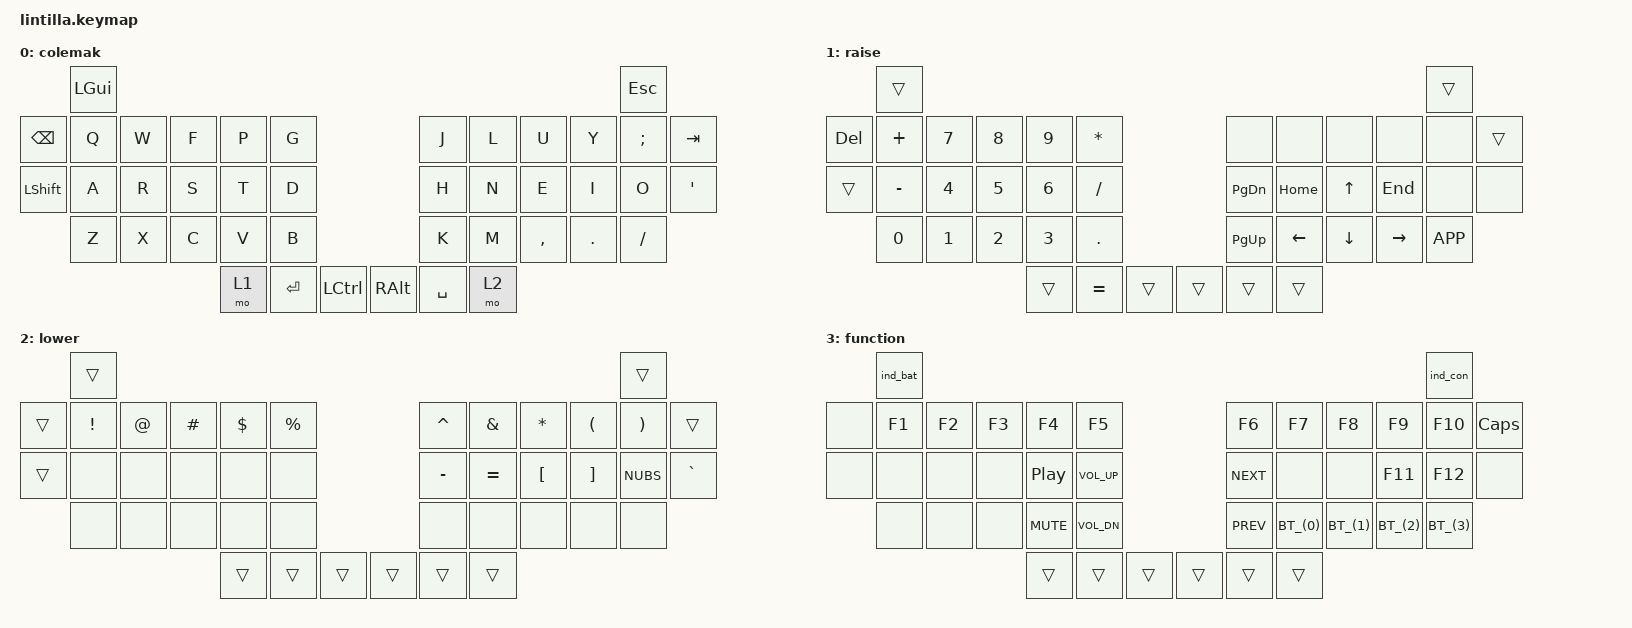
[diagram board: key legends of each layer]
#include <behaviors.dtsi>
#include <dt-bindings/zmk/bt.h>
#include <dt-bindings/zmk/keys.h>
#include <dt-bindings/zmk/outputs.h>
#include <behaviors/rgbled_widget.dtsi>

// Multiple mods
#define GS(key) &kp LG(LS(key))
#define GCS(key) &kp LG(LC(LS(key)))
#define HYPR(key) &kp LG(LA(LC(LS(key))))

// Shortcuts for home row mods
#define Glb &hm GLOBE
#define Sft &hm LSHFT
#define Ctl &hm LCTRL
#define Opt &hm LALT
#define Cmd &hm LGUI
#define Alt &hm RALT
 
// Magic bluetooth button
#define BT_(btnum) &bt_key btnum btnum

/ {
    behaviors {
        bt_key: magic_bluetooth_key {
            compatible = "zmk,behavior-hold-tap";
            #binding-cells = <2>;
            flavor = "tap-preferred";
            tapping-term-ms = <500>;
            bindings = <&bt_clr>, <&bt_sel>;
        };

        hm: homerow_mod {
            compatible = "zmk,behavior-hold-tap";
            #binding-cells = <2>;
            tapping-term-ms = <300>;
            require-prior-idle-ms = <150>;
            quick-tap-ms = <0>;
            flavor = "tap-preferred";
            bindings = <&kp>, <&kp>;
        };

        lsscw: layer_sticky_shift_caps_word {
            compatible = "zmk,behavior-hold-tap";
            #binding-cells = <2>;
            flavor = "balanced";
            tapping-term-ms = <200>;
            bindings = <&mo>, <&sscw>;
        };

        mcs: mod_comma_semi {
            compatible = "zmk,behavior-mod-morph";
            #binding-cells = <0>;
            bindings = <&kp COMMA>, <&kp SEMI>;
            mods = <(MOD_LSFT|MOD_RSFT)>;
        };

        mdc: mod_dot_colon {
            compatible = "zmk,behavior-mod-morph";
            #binding-cells = <0>;
            bindings = <&kp DOT>, <&kp COLON>;
            mods = <(MOD_LSFT|MOD_RSFT)>;
        };

        msb: mod_slash_back {
            compatible = "zmk,behavior-mod-morph";
            #binding-cells = <0>;
            bindings = <&kp SLASH>, <&kp BACKSLASH>;
            mods = <(MOD_LSFT|MOD_RSFT)>;
        };

        sscw: sticky_shift_caps_word {
            compatible = "zmk,behavior-mod-morph";
            #binding-cells = <0>;
            bindings = <&sk LSHIFT>, <&caps_word>;
            mods = <(MOD_LSFT|MOD_RSFT)>;
        };
    };

    conditional_layers {
        compatible = "zmk,conditional-layers";
        function_layer {
            if-layers = <1 2>;
            then-layer = <3>;
        };
    };

    macros {
        bt_clr: bluetooth_clear {
            compatible = "zmk,behavior-macro-one-param";
            #binding-cells = <1>;
            bindings = <&macro_param_1to1 &bt_sel MACRO_PLACEHOLDER>, <&bt BT_CLR>;
        };

        bt_sel: bluetooth_select {
            compatible = "zmk,behavior-macro-one-param";
            #binding-cells = <1>;
            bindings = <&out OUT_BLE>, <&macro_param_1to2 &bt BT_SEL MACRO_PLACEHOLDER>;
        };

        flash: dongle_bootloader {
            compatible = "zmk,behavior-macro-one-param";
            #binding-cells = <1>;
            bindings = <&macro_param_1to1 &to MACRO_PLACEHOLDER>, <&bootloader>;
        };
    };

    keymap {
        compatible = "zmk,keymap";

        qwerty {
//                       ┏━━━━━━━━━━━━━━━━━━━━━━━━━┓
            display-name = "colemak"                ;
//                       ┗━━━━━━━━━━━━━━━━━━━━━━━━━┛
            bindings = <
//         ┏━━━━━━━┓                                                                                          ┏━━━━━━━┓
//         ┃  WIN  ┃                                                                                          ┃  ESC  ┃
            &kp LGUI                                                                                           &kp ESC
//         ┃       ┃                                                                                          ┃       ┃
// ┏━━━━━━━╋━━━━━━━╋━━━━━━━┳━━━━━━━┳━━━━━━━┳━━━━━━━┓                          ┏━━━━━━━┳━━━━━━━┳━━━━━━━┳━━━━━━━╋━━━━━━━╋━━━━━━━┓
// ┃  BSPC ┃   Q   ┃   W   ┃   F   ┃   P   ┃   G   ┃                          ┃   J   ┃   L   ┃   U   ┃   Y   ┃   :   ┃  TAB  ┃
   &kp BSPC  &kp Q   &kp W   &kp F   &kp P   &kp G                              &kp J   &kp L   &kp U   &kp Y  &kp SEMI &kp TAB
// ┣━━━━━━━╋━━━━━━━╋━━━━━━━╋━━━━━━━╋━━━━━━━╋━━━━━━━┫                          ┣━━━━━━━╋━━━━━━━╋━━━━━━━╋━━━━━━━╋━━━━━━━╋━━━━━━━┫
// ┃ SHIFT ┃   A   ┃   R   ┃   S   ┃   T   ┃   D   ┃                          ┃   H   ┃   N   ┃   E   ┃   I   ┃   O   ┃   '   ┃
  &kp LSHFT  &kp A   &kp R   &kp S   &kp T   &kp D                              &kp H   &kp N   &kp E   &kp I  &kp O   &kp SQT
// ┃       ┃       ┃       ┃       ┃       ┃       ┃                          ┃       ┃       ┃       ┃       ┃       ┃       ┃
// ┗━━━━━━━╋━━━━━━━╋━━━━━━━╋━━━━━━━╋━━━━━━━╋━━━━━━━┫                          ┣━━━━━━━╋━━━━━━━╋━━━━━━━╋━━━━━━━╋━━━━━━━╋━━━━━━━┛
//         ┃   Z   ┃   X   ┃   C   ┃   V   ┃   B   ┃                          ┃   K   ┃   M   ┃   ,   ┃   .   ┃  / \  ┃
             &kp Z   &kp X   &kp C   &kp V   &kp B                              &kp K   &kp M &kp COMMA &kp DOT &kp FSLH
//         ┗━━━━━━━┻━━━━━━━┻━━━━━━━┻━━━┳━━━┻━━━┳━━━┻━━━┳━━━━━━━┓  ┏━━━━━━━┳━━━┻━━━┳━━━┻━━━┳━━━┻━━━━━━━┻━━━━━━━┻━━━━━━━┛
//                                     ┃ RAISE ┃  RET  ┃ L CTL ┃  ┃ RALT  ┃ SPACE ┃ LOWER ┃
                                         &mo 1  &kp RET &kp LCTL  &kp RALT &kp SPACE &mo  2
//                                     ┗━━━━━━━┫       ┣━━━━━━━┛  ┗━━━━━━━┫       ┣━━━━━━━┛
//                                             ┗━━━━━━━┛                  ┗━━━━━━━┛
            >;
        };

        num {
//                       ┏━━━━━━━━━━━━━━━━━━━━━━━━━┓
            display-name = "raise"                ;
//                       ┗━━━━━━━━━━━━━━━━━━━━━━━━━┛
            bindings = <
//         ┏━━━━━━━┓                                                                                          ┏━━━━━━━┓
//         ┃       ┃                                                                                          ┃       ┃
             &trans                                                                                             &trans
// ┏━━━━━━━╋━━━━━━━╋━━━━━━━┳━━━━━━━┳━━━━━━━┳━━━━━━━┓                          ┏━━━━━━━┳━━━━━━━┳━━━━━━━┳━━━━━━━╋━━━━━━━╋━━━━━━━┓
// ┃  DEL  ┃   +   ┃   7   ┃   8   ┃   9   ┃   *   ┃                          ┃       ┃       ┃       ┃       ┃       ┃       ┃
   &kp DEL &kp PLUS &kp N7 &kp N8  &kp N9 &kp STAR                              &none   &none   &none   &none   &none   &trans
// ┣━━━━━━━╋━━━━━━━╋━━━━━━━╋━━━━━━━╋━━━━━━━╋━━━━━━━┫                          ┣━━━━━━━╋━━━━━━━╋━━━━━━━╋━━━━━━━╋━━━━━━━╋━━━━━━━┫
// ┃       ┃   -   ┃   4   ┃   5   ┃   6   ┃   /   ┃                          ┃  PGUP ┃ HOME  ┃   UP  ┃ END   ┃       ┃       ┃
    &trans &kp MINUS &kp N4  &kp N5  &kp N6 &kp FSLH                         &kp PG_DN &kp HOME &kp UP &kp END  &none   &none
// ┃       ┃       ┃       ┃       ┃       ┃       ┃                          ┃       ┃       ┃       ┃       ┃       ┃       ┃
// ┗━━━━━━━╋━━━━━━━╋━━━━━━━╋━━━━━━━╋━━━━━━━╋━━━━━━━┫                          ┣━━━━━━━╋━━━━━━━╋━━━━━━━╋━━━━━━━╋━━━━━━━╋━━━━━━━┛
//         ┃   0   ┃   1   ┃   2   ┃   3   ┃   .   ┃                          ┃  PGDN ┃  LEFT ┃  DOWN ┃ RIGHT ┃ RAPP  ┃
            &kp N0  &kp N1   &kp N2  &kp N3 &kp DOT                          &kp PG_UP &kp LEFT &kp DOWN &kp RIGHT &kp K_APP
//         ┗━━━━━━━┻━━━━━━━┻━━━━━━━┻━━━┳━━━┻━━━┳━━━┻━━━┳━━━━━━━┓  ┏━━━━━━━┳━━━┻━━━┳━━━┻━━━┳━━━┻━━━━━━━┻━━━━━━━┻━━━━━━━┛
//                                     ┃       ┃   =   ┃       ┃  ┃       ┃       ┃       ┃
                                        &trans &kp EQUAL &trans     &trans  &trans  &trans
//                                     ┗━━━━━━━┫       ┣━━━━━━━┛  ┗━━━━━━━┫       ┣━━━━━━━┛
//                                             ┗━━━━━━━┛                  ┗━━━━━━━┛
            >;
        };

        nav {
//                       ┏━━━━━━━━━━━━━━━━━━━━━━━━━┓
            display-name = "lower"                 ;
//                       ┗━━━━━━━━━━━━━━━━━━━━━━━━━┛
            bindings = <
//         ┏━━━━━━━┓                                                                                          ┏━━━━━━━┓
//         ┃       ┃                                                                                          ┃       ┃
             &trans                                                                                            &trans
// ┏━━━━━━━╋━━━━━━━╋━━━━━━━┳━━━━━━━┳━━━━━━━┳━━━━━━━┓                          ┏━━━━━━━┳━━━━━━━┳━━━━━━━┳━━━━━━━╋━━━━━━━╋━━━━━━━┓
// ┃       ┃   !   ┃   @   ┃   #   ┃   $   ┃   %   ┃                          ┃   ^   ┃   &   ┃   *   ┃   (   ┃   )   ┃       ┃
     &trans  &kp EXCL &kp AT &kp HASH &kp DLLR &kp PRCNT                        &kp CARET &kp AMPS &kp STAR &kp LPAR &kp RPAR &trans
// ┣━━━━━━━╋━━━━━━━╋━━━━━━━╋━━━━━━━╋━━━━━━━╋━━━━━━━┫                          ┣━━━━━━━╋━━━━━━━╋━━━━━━━╋━━━━━━━╋━━━━━━━╋━━━━━━━┫
// ┃       ┃       ┃       ┃       ┃       ┃       ┃                          ┃  - _  ┃  + =  ┃ [ {   ┃  ] }  ┃  \ |  ┃  ` ~  ┃
     &trans   &none   &none   &none   &none   &none                          &kp MINUS &kp EQUAL &kp LBKT &kp RBKT &kp NUBS &kp GRAVE
// ┃       ┃       ┃       ┃       ┃       ┃       ┃                          ┃       ┃       ┃       ┃       ┃       ┃       ┃
// ┗━━━━━━━╋━━━━━━━╋━━━━━━━╋━━━━━━━╋━━━━━━━╋━━━━━━━┫                          ┣━━━━━━━╋━━━━━━━╋━━━━━━━╋━━━━━━━╋━━━━━━━╋━━━━━━━┛
//         ┃       ┃       ┃       ┃       ┃       ┃                          ┃       ┃       ┃       ┃       ┃       ┃
             &none   &none   &none   &none   &none                              &none   &none   &none   &none   &none
//         ┗━━━━━━━┻━━━━━━━┻━━━━━━━┻━━━┳━━━┻━━━┳━━━┻━━━┳━━━━━━━┓  ┏━━━━━━━┳━━━┻━━━┳━━━┻━━━┳━━━┻━━━━━━━┻━━━━━━━┻━━━━━━━┛
//                                     ┃       ┃       ┃       ┃  ┃       ┃       ┃       ┃
                                         &trans  &trans  &trans     &trans  &trans  &trans
//                                     ┗━━━━━━━┫       ┣━━━━━━━┛  ┗━━━━━━━┫       ┣━━━━━━━┛
//                                             ┗━━━━━━━┛                  ┗━━━━━━━┛
            >;
        };

        fn {
//                       ┏━━━━━━━━━━━━━━━━━━━━━━━━━┓
            display-name = "function"              ;
//                       ┗━━━━━━━━━━━━━━━━━━━━━━━━━┛
            bindings = <
//         ┏━━━━━━━┓                                                                                          ┏━━━━━━━┓
//         ┃Battery┃                                                                                          ┃CON LED┃
            &ind_bat                                                                                           &ind_con
// ┏━━━━━━━╋━━━━━━━╋━━━━━━━┳━━━━━━━┳━━━━━━━┳━━━━━━━┓                          ┏━━━━━━━┳━━━━━━━┳━━━━━━━┳━━━━━━━╋━━━━━━━╋━━━━━━━┓
// ┃       ┃  F1   ┃  F2   ┃  F3   ┃   F4  ┃  F5   ┃                          ┃  F6   ┃   F7  ┃  F8   ┃  F9   ┃  F10  ┃ CPSLK ┃
     &none   &kp F1 &kp F2  &kp F3  &kp F4   &kp F5                            &kp F6  &kp F7  &kp F8  &kp F9  &kp F10 &kp CAPS
// ┣━━━━━━━╋━━━━━━━╋━━━━━━━╋━━━━━━━╋━━━━━━━╋━━━━━━━┫                          ┣━━━━━━━╋━━━━━━━╋━━━━━━━╋━━━━━━━╋━━━━━━━╋━━━━━━━┫
// ┃SCRNSHT┃       ┃       ┃       ┃  PLAY ┃  VOL+ ┃                          ┃  NEXT ┃       ┃       ┃  F11  ┃  F12  ┃TSKMNGR┃
     &none   &none  &none   &none &kp C_PP &kp C_VOL_UP                      &kp C_NEXT &none   &none  &kp F11 &kp F12  &none
// ┗━━━━━━━╋━━━━━━━╋━━━━━━━╋━━━━━━━╋━━━━━━━╋━━━━━━━┫                          ┣━━━━━━━╋━━━━━━━╋━━━━━━━╋━━━━━━━╋━━━━━━━╋━━━━━━━┛
//         ┃       ┃       ┃       ┃  MUTE ┃  VOL- ┃                          ┃  PRVS ┃  BT1  ┃  BT2  ┃  BT3  ┃  BT4  ┃
            &none   &none   &none &kp C_MUTE &kp C_VOL_DN                     &kp C_PREV BT_(0)  BT_(1)  BT_(2)  BT_(3)
//         ┗━━━━━━━┻━━━━━━━┻━━━━━━━┻━━━┳━━━┻━━━┳━━━┻━━━┳━━━━━━━┓  ┏━━━━━━━┳━━━┻━━━┳━━━┻━━━┳━━━┻━━━━━━━┻━━━━━━━┻━━━━━━━┛
//                                     ┃       ┃       ┃       ┃  ┃       ┃       ┃       ┃
                                         &trans  &trans  &trans    &trans  &trans   &trans
//                                     ┗━━━━━━━┫       ┣━━━━━━━┛  ┗━━━━━━━┫       ┣━━━━━━━┛
//                                             ┗━━━━━━━┛                  ┗━━━━━━━┛
            >;
        };

  
        // Extra empty layers for ZMK Studio
    };
};

// vim: expandtab softtabstop=4 shiftwidth=4 filetype=dts
